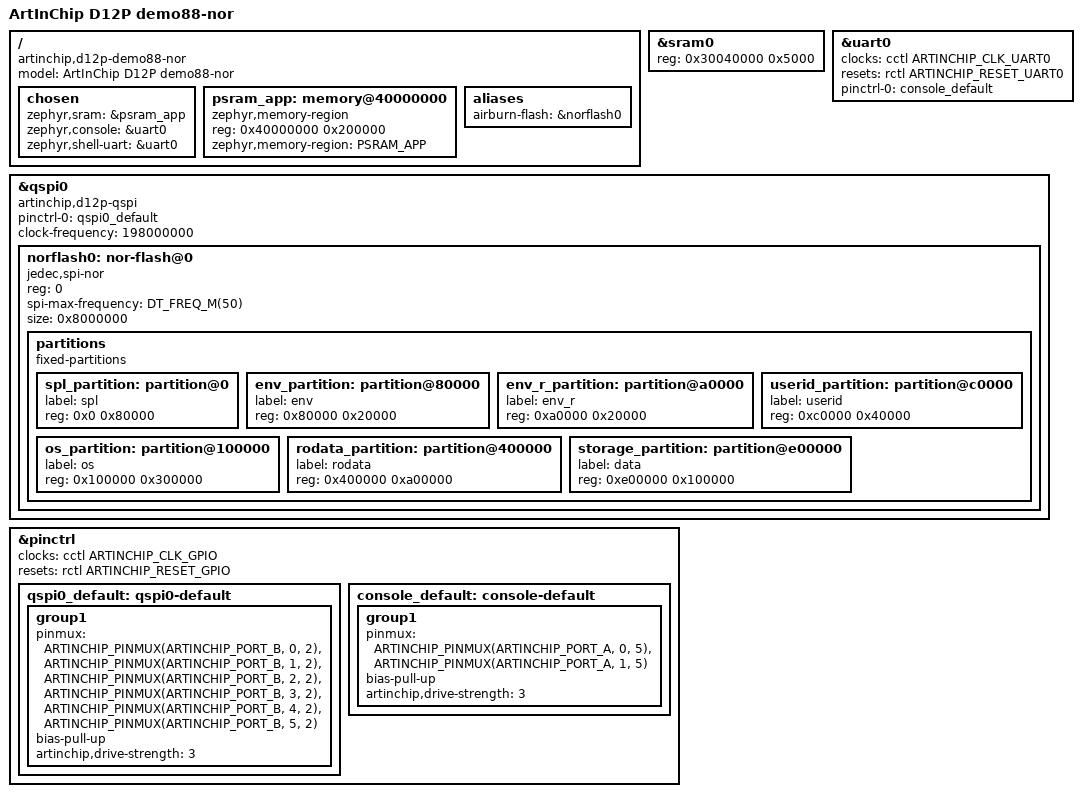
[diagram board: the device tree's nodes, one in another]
/*
 * SPDX-FileCopyrightText: Copyright (c) 2026 UltraSemi Technology Development Co., Ltd.
 * SPDX-License-Identifier: Apache-2.0
 */

/dts-v1/;

#include <artinchip/d12p.dtsi>
#include <zephyr/dt-bindings/pinctrl/artinchip-pinctrl.h>

/* Source: Luban-Lite c06865a38ca8bcffa337eee7b209651abacf45d6, target/d12p/demo88-nor. */
/ {
	model = "ArtInChip D12P demo88-nor";
	compatible = "artinchip,d12p-demo88-nor";

	chosen {
		zephyr,sram = &psram_app;
		zephyr,console = &uart0;
		zephyr,shell-uart = &uart0;
	};

	/* PBP initializes PSRAM before loading the application. */
	psram_app: memory@40000000 {
		compatible = "zephyr,memory-region";
		reg = <0x40000000 0x200000>;
		zephyr,memory-region = "PSRAM_APP";
	};
};

&sram0 {
	reg = <0x30040000 0x5000>;
};

&uart0 {
	status = "okay";
};

/* Metadata for the vendor loader; QSPI stays disabled in this baseline. */
/ {
	aliases {
		airburn-flash = &norflash0;
	};
};

&qspi0 {
	norflash0: nor-flash@0 {
		compatible = "jedec,spi-nor";
		reg = <0>;
		spi-max-frequency = <DT_FREQ_M(50)>;
		size = <0x8000000>; /* bits */

		partitions {
			compatible = "fixed-partitions";
			#address-cells = <1>;
			#size-cells = <1>;

			spl_partition: partition@0 {
				label = "spl";
				reg = <0x0 0x80000>;
			};

			env_partition: partition@80000 {
				label = "env";
				reg = <0x80000 0x20000>;
			};

			env_r_partition: partition@a0000 {
				label = "env_r";
				reg = <0xa0000 0x20000>;
			};

			userid_partition: partition@c0000 {
				label = "userid";
				reg = <0xc0000 0x40000>;
			};

			os_partition: partition@100000 {
				label = "os";
				reg = <0x100000 0x300000>;
			};

			rodata_partition: partition@400000 {
				label = "rodata";
				reg = <0x400000 0xa00000>;
			};

			storage_partition: partition@e00000 {
				label = "data";
				reg = <0xe00000 0x100000>;
			};
		};
	};
};

/* Native SPI0 on external NOR PB0--PB5, matching the vendor demo config. */
&pinctrl {
	qspi0_default: qspi0-default {
		group1 {
			pinmux = <ARTINCHIP_PINMUX(ARTINCHIP_PORT_B, 0, 2)>,
				 <ARTINCHIP_PINMUX(ARTINCHIP_PORT_B, 1, 2)>,
				 <ARTINCHIP_PINMUX(ARTINCHIP_PORT_B, 2, 2)>,
				 <ARTINCHIP_PINMUX(ARTINCHIP_PORT_B, 3, 2)>,
				 <ARTINCHIP_PINMUX(ARTINCHIP_PORT_B, 4, 2)>,
				 <ARTINCHIP_PINMUX(ARTINCHIP_PORT_B, 5, 2)>;
			bias-pull-up;
			artinchip,drive-strength = <3>;
		};
	};
};
&qspi0 {
	pinctrl-0 = <&qspi0_default>;
	pinctrl-names = "default";
};

&uart0 {
	/delete-property/ artinchip,bootloader-configured;
	clocks = <&cctl ARTINCHIP_CLK_UART0>;
	resets = <&rctl ARTINCHIP_RESET_UART0>;
	pinctrl-0 = <&console_default>;
	pinctrl-names = "default";
};
&pinctrl {
	clocks = <&cctl ARTINCHIP_CLK_GPIO>;
	resets = <&rctl ARTINCHIP_RESET_GPIO>;
	console_default: console-default {
		group1 {
			pinmux = <ARTINCHIP_PINMUX(ARTINCHIP_PORT_A, 0, 5)>,
				 <ARTINCHIP_PINMUX(ARTINCHIP_PORT_A, 1, 5)>;
			bias-pull-up;
			artinchip,drive-strength = <3>;
		};
	};
};
&qspi0 {
	compatible = "artinchip,d12p-qspi", "artinchip,d13x-qspi";
	clock-frequency = <198000000>;
};
